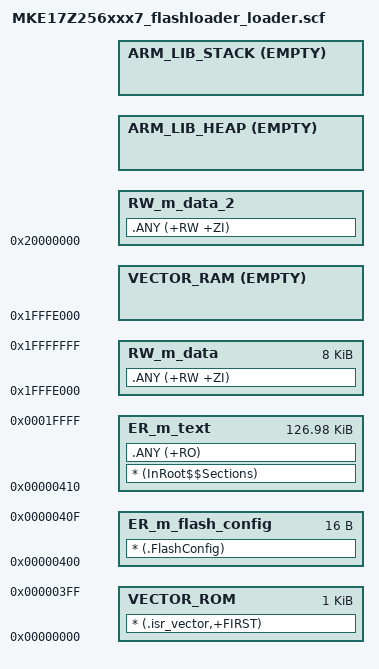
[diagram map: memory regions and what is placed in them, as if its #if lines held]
#!armclang --target=arm-arm-none-eabi -mcpu=cortex-m0plus -E -x c
/*
** ###################################################################
**     Processors:          MKE17Z256VLH7
**                          MKE17Z256VLL7
**
**     Compiler:            Keil ARM C/C++ Compiler
**     Reference manual:    KE1xZP100M72SF1RM, Rev. 0, Dec. 2020
**     Version:             rev. 1.0, 2020-12-10
**     Build:               b201210
**
**     Abstract:
**         Linker file for the Keil ARM C/C++ Compiler
**
**     Copyright 2016 Freescale Semiconductor, Inc.
**     Copyright 2016-2020 NXP
**     All rights reserved.
**
**     SPDX-License-Identifier: BSD-3-Clause
**
**     http:                 www.nxp.com
**     mail:                 support@nxp.com
**
** ###################################################################
*/


#define m_interrupts_start             0x00000000
#define m_interrupts_size              0x00000400

#define m_flash_config_start           0x00000400
#define m_flash_config_size            0x00000010

#define m_text_start                   0x00000410
#define m_text_size                    0x0001FBF0

#define m_interrupts_ram_start         0x1FFFE000
#define m_interrupts_ram_size          0x0

#define m_data_start                   (m_interrupts_ram_start + m_interrupts_ram_size)
#define m_data_size                    (0x00002000 - m_interrupts_ram_size)

#define m_data_2_start                 0x20000000
#define m_data_2_size                  0x00006000

/* Sizes */
#if (defined(__stack_size__))
  #define Stack_Size                   __stack_size__
#else
  #define Stack_Size                   0x0400
#endif

#if (defined(__heap_size__))
  #define Heap_Size                    __heap_size__
#else
  #define Heap_Size                    0x0
#endif

LR_m_text m_text_start m_text_size {   ; load region size_region
  ER_m_text m_text_start m_text_size { ; load address = execution address
    * (InRoot$$Sections)
    .ANY (+RO)
  }
  RW_m_data m_data_start m_data_size { ; RW data
    .ANY (+RW +ZI)
  }
  RW_m_data_2 m_data_2_start m_data_2_size-Stack_Size-Heap_Size { ; RW data
    .ANY (+RW +ZI)
  }
  ARM_LIB_HEAP ((ImageLimit(RW_m_data_2) == m_data_2_start) ? ImageLimit(RW_m_data) : +0) EMPTY Heap_Size { ; Heap region growing up
  }
  ARM_LIB_STACK m_data_2_start+m_data_2_size-Stack_Size EMPTY -Stack_Size { ; Stack region growing down
  }
}


LR_m_interrupts m_interrupts_start m_interrupts_size {
  VECTOR_ROM m_interrupts_start m_interrupts_size { ; load address = execution address
    * (.isr_vector,+FIRST)
  }
}

LR_m_flash_config m_flash_config_start m_flash_config_size {
  ER_m_flash_config m_flash_config_start m_flash_config_size { ; load address = execution address
    * (.FlashConfig)
  }
}

LR_m_interrupts_ram m_interrupts_ram_start m_interrupts_ram_size {
  VECTOR_RAM m_interrupts_ram_start EMPTY m_interrupts_ram_size {
  }
}

